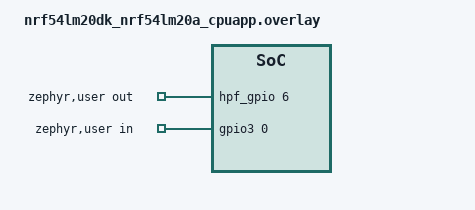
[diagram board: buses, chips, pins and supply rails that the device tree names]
/*
 * Copyright (c) 2026 Nordic Semiconductor ASA
 *
 * SPDX-License-Identifier: LicenseRef-Nordic-5-Clause
 */

/* Test requires GPIO loopback:
 * - between P2.06 and P3.00,
 */

/delete-node/ &led1;

/ {
	zephyr,user {
		out-gpios = <&hpf_gpio 6 GPIO_ACTIVE_HIGH>;
		in-gpios = <&gpio3 0 GPIO_ACTIVE_HIGH>;
	};

	aliases {
		led = &led0;
		/delete-property/ led1;
	};
};

&gpiote20 {
	status = "okay";
};

&gpio3 {
	status = "okay";
};
